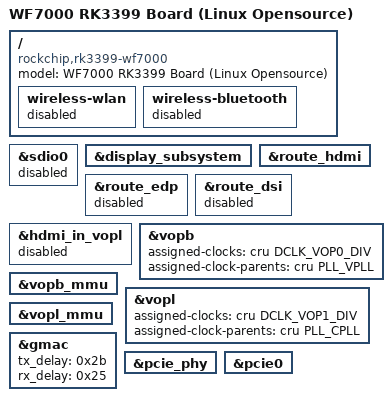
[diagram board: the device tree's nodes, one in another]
// SPDX-License-Identifier: (GPL-2.0+ OR MIT)
/*
 * WF7000 RK3399 board (Rockchip Sapphire / Excavator based)
 *
 * Target kernel : unifreq/linux-6.1.y-rockchip
 * Display path  : VOPB -> HDMI  (eDP and DSI routes off)
 *
 * The two included dtsi files already describe this board almost completely:
 *   rk3399-sapphire.dtsi : rk808 + syr827/828, gmac, sdhci(8bit hs400),
 *                          sdmmc, USB (dwc3_0/1, u2phy0/1, tcphy0/1, ehci/ohci),
 *                          fusb302 Type-C on i2c4@0x22, vcc5v0_host (GPIO4_D1),
 *                          cdn-dp, vopb/vopl, hdmi + hdmi_sound, gpu, tsadc,
 *                          adc-keys (saradc ch1), gpio power key (GPIO0_A5)
 *   rk3399-excavator-sapphire.dtsi : rt5651 codec + multicodecs sound card,
 *                          i2s0, spdif, sdio0, dmc/dfi
 *   rk3399-linux.dtsi    : display_subsystem + route_hdmi/edp/dsi, fiq-debugger,
 *                          ramoops, vpu/rga
 *
 * So this file only carries the board-specific deltas.
 *
 * Build:
 *   cp rk3399-wf7000.dts arch/arm64/boot/dts/rockchip/
 *   make ARCH=arm64 CROSS_COMPILE=aarch64-linux-gnu- rockchip/rk3399-wf7000.dtb
 */

/dts-v1/;

#include "rk3399-excavator-sapphire.dtsi"
#include "rk3399-linux.dtsi"

/ {
	model = "WF7000 RK3399 Board (Linux Opensource)";
	compatible = "rockchip,rk3399-wf7000", "rockchip,rk3399";

	/*
	 * This board has no wifi/BT module. The excavator dtsi turns on sdio0
	 * (ap6354) and the wlan/bluetooth platdata by default; switch them off.
	 * (These two nodes have no label, so they must be overridden by name.)
	 */
	wireless-wlan {
		status = "disabled";
	};

	wireless-bluetooth {
		status = "disabled";
	};
};

&sdio0 {
	status = "disabled";
};

/* ---------------------------------------------------------------- display */

&display_subsystem {
	status = "okay";
};

/* route_hdmi connects to <&vopb_out_hdmi>, route_edp to <&vopl_out_edp> */
&route_hdmi {
	status = "okay";
};

&route_edp {
	status = "disabled";
};

&route_dsi {
	status = "disabled";
};

&hdmi_in_vopl {
	status = "disabled";
};

/*
 * VOPB drives HDMI, so source it from VPLL to get exact TMDS clocks.
 * (rk3399-sapphire.dtsi leaves both VOPs without assigned clock parents,
 *  and the Excavator default is the other way round: VOPB->CPLL, VOPL->VPLL.)
 */
&vopb {
	status = "okay";
	assigned-clocks = <&cru DCLK_VOP0_DIV>;
	assigned-clock-parents = <&cru PLL_VPLL>;
};

&vopb_mmu {
	status = "okay";
};

&vopl {
	status = "okay";
	assigned-clocks = <&cru DCLK_VOP1_DIV>;
	assigned-clock-parents = <&cru PLL_CPLL>;
};

&vopl_mmu {
	status = "okay";
};

/* ---------------------------------------------------------------- ethernet */

/*
 * Board-specific RGMII delays. rk3399-sapphire.dtsi uses tx_delay = <0x28>
 * rx_delay = <0x11>; the vendor blob for this board uses 0x2b / 0x25.
 * Wrong values => link up but massive packet loss, or no link at all.
 * PHY reset is GPIO3_PB7 in both.
 */
&gmac {
	tx_delay = <0x2b>;
	rx_delay = <0x25>;
};

/* ---------------------------------------------------------------- pcie */

&pcie_phy {
	status = "okay";
};

&pcie0 {
	status = "okay";
};

/*
 * ------------------------------------------------------------------ notes
 *
 * Not migrated from the vendor wf7000.dts (no binding in this kernel):
 *   - gh_gpio_sel   : gpio1 RK_PD2/RK_PD5/RK_PD6 mux select (custom driver)
 *   - led_ctrl      : gpio4 RK_PB5 (custom driver)
 *   - rockchip-key  : replaced by the dtsi adc-keys (saradc ch1, 6 buttons)
 *   - remotectl-pwm : IR receiver on pwm3 (ff420030)
 *
 * If this board is populated with ES8316 instead of RT5651, replace the
 * codec on i2c1 (the dtsi already provides rt5651@1a):
 *
 * &i2c1 {
 *	rt5651@1a { status = "disabled"; };
 *	es8316: es8316@10 {
 *		compatible = "everest,es8316";
 *		reg = <0x10>;
 *		clocks = <&cru SCLK_I2S_8CH_OUT>;
 *		clock-names = "mclk";
 *		#sound-dai-cells = <0>;
 *	};
 * };
 * and point rt5651_sound's rockchip,codec at &es8316 instead of &rt5651.
 *
 * If the LED is needed, add a standard gpio-leds node:
 *
 * / {
 *	leds {
 *		compatible = "gpio-leds";
 *		work-led {
 *			gpios = <&gpio4 RK_PB5 GPIO_ACTIVE_HIGH>;
 *			default-state = "on";
 *		};
 *	};
 * };
 */
